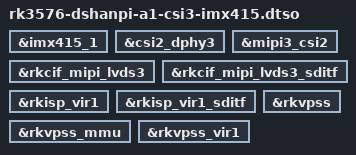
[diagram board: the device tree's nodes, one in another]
/dts-v1/;
/plugin/;
/ {
	fragment@0 {
		target = <&imx415_1>;
		__overlay__ {
			status = "okay";
		};
	};

	fragment@1 {
		target = <&csi2_dphy3>;
		__overlay__ {
			status = "okay";
		};
	};

	fragment@2 {
		target = <&mipi3_csi2>;
		__overlay__ {
	
			status = "okay";
		};
	};

	fragment@3 {
		target = <&rkcif_mipi_lvds3>;
		__overlay__ {
			status = "okay";
		};
	};

	fragment@4 {
		target = <&rkcif_mipi_lvds3_sditf>;
		__overlay__ {
			status = "okay";
		};
	};

	fragment@5 {
		target = <&rkisp_vir1>;
		__overlay__ {
			status = "okay";
		};
	};

	fragment@6 {
		target = <&rkisp_vir1_sditf>;
		__overlay__ {
			status = "okay";
		};
	};

	fragment@7 {
		target = <&rkvpss>;
		__overlay__ {
			status = "okay";
		};
	};

	fragment@8 {
		target = <&rkvpss_mmu>;
		__overlay__ {
			status = "okay";
		};
	};
	
	fragment@9 {
		target = <&rkvpss_vir1>;
		__overlay__ {
			status = "okay";
		};
	};
};
